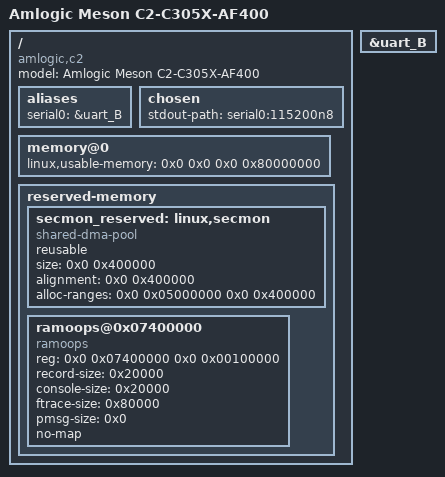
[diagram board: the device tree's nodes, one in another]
// SPDX-License-Identifier: (GPL-2.0+ OR MIT)
/*
 * Copyright (c) 2019 Amlogic, Inc. All rights reserved.
 */

/dts-v1/;

#include "meson-c2.dtsi"

/ {
	compatible = "amlogic,c2";
	model = "Amlogic Meson C2-C305X-AF400";

	aliases {
		serial0 = &uart_B;
	};

	chosen {
		stdout-path = "serial0:115200n8";
	};

	memory@0 {
		device_type = "memory";
		linux,usable-memory = <0x0 0x0 0x0 0x80000000>;
	};

	reserved-memory {
		#address-cells = <2>;
		#size-cells = <2>;
		ranges;
		secmon_reserved:linux,secmon {
			compatible = "shared-dma-pool";
			reusable;
			size = <0x0 0x400000>;
			alignment = <0x0 0x400000>;
			alloc-ranges = <0x0 0x05000000 0x0 0x400000>;
		};

		ramoops@0x07400000 {
			compatible = "ramoops";
			reg = <0x0 0x07400000 0x0 0x00100000>;
			record-size = <0x20000>;
			console-size = <0x20000>;
			ftrace-size = <0x80000>;
			pmsg-size = <0x0>;
			no-map;
		};
	};
};

&uart_B {
	status = "okay";
};
